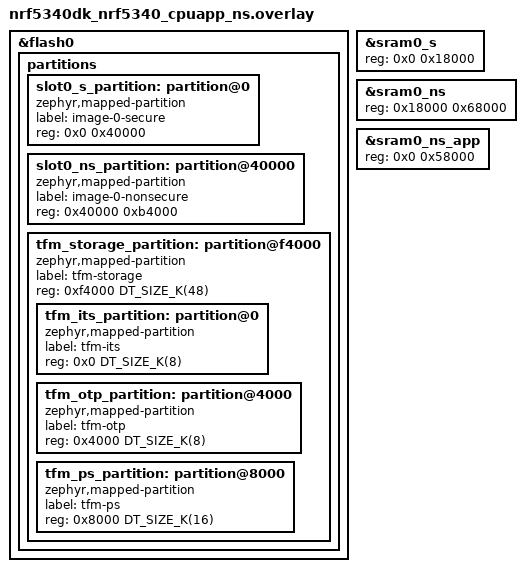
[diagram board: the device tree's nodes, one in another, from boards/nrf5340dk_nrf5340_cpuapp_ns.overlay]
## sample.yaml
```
sample:
  description: Wi-Fi Fundamentals Course by Nordic Developer Academy (https://academy.nordicsemi.com/)
  name: Wi-Fi Fundamentals Course - Lesson 2 Exercise 2 Solution
  
common: 
    sysbuild: true
    build_only: true
    
tests:
  wifi_fund.l2.e2_sol.nrf5340dk: 
    extra_args: SHIELD=nrf7002ek
    integration_platforms: 
      - nrf5340dk/nrf5340/cpuapp/ns
      - nrf5340dk/nrf5340/cpuapp
    platform_allow:
      - nrf5340dk/nrf5340/cpuapp/ns
      - nrf5340dk/nrf5340/cpuapp
  
  wifi_fund.l2.e2_sol.nrf7002dk:
    integration_platforms: 
      - nrf7002dk/nrf5340/cpuapp/ns
      - nrf7002dk/nrf5340/cpuapp    
    platform_allow:
      - nrf7002dk/nrf5340/cpuapp/ns
      - nrf7002dk/nrf5340/cpuapp
  
```

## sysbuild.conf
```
#
# Copyright (c) 2024 Nordic Semiconductor ASA
#
# SPDX-License-Identifier: LicenseRef-Nordic-5-Clause
#

# STEP 1.1 - Enable Wi-Fi in Sysbuild
SB_CONFIG_WIFI_NRF70=y
```

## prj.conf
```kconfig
#
# Copyright (c) 2022 Nordic Semiconductor ASA
#
# SPDX-License-Identifier: LicenseRef-Nordic-5-Clause
#

# Wi-Fi
# STEP 1.2 - Enable the Wi-Fi relevant configurations
CONFIG_WIFI=y
CONFIG_WIFI_NM_WPA_SUPPLICANT=y

# STEP 1.3 - Optimize Wi-Fi stack to save memory
CONFIG_NRF70_RX_NUM_BUFS=16
CONFIG_NRF70_MAX_TX_AGGREGATION=4

# STEP 2 - Configure the Wi-Fi credentials
CONFIG_WIFI_CREDENTIALS=y
# STEP 12.1 - Disable static Wi-Fi network configuration
CONFIG_WIFI_CREDENTIALS_STATIC=n
CONFIG_WIFI_CREDENTIALS_STATIC_SSID="<your_network_SSID>"
CONFIG_WIFI_CREDENTIALS_STATIC_PASSWORD="<your_network_password>"

# STEP 1.4 - Enable the Network Management relevant configurations
CONFIG_NET_MGMT=y
CONFIG_NET_MGMT_EVENT=y
CONFIG_NET_MGMT_EVENT_INFO=y

# STEP 1.5 - Enable the Connection Manager and L2 connectivity
CONFIG_NET_CONNECTION_MANAGER=y
CONFIG_NET_CONNECTION_MANAGER_MONITOR_STACK_SIZE=5200
CONFIG_L2_WIFI_CONNECTIVITY=y
# STEP 14 - Enable the auto connect feature of the L2 Wi-Fi connectivity
CONFIG_L2_WIFI_CONNECTIVITY_AUTO_CONNECT=n

# STEP 13 - Enable support for shell commands
CONFIG_SHELL=y
CONFIG_NET_L2_WIFI_SHELL=y
CONFIG_WIFI_CREDENTIALS_SHELL=y
CONFIG_SHELL_STACK_SIZE=5200

# Logging
CONFIG_LOG=y

# DK library
CONFIG_DK_LIBRARY=y

# System settings
CONFIG_NEWLIB_LIBC=y
CONFIG_NEWLIB_LIBC_NANO=n

# Networking
CONFIG_NETWORKING=y
CONFIG_NET_SOCKETS=y
CONFIG_NET_L2_ETHERNET=y
CONFIG_NET_IPV4=y
CONFIG_NET_IPV6=n
CONFIG_NET_DHCPV4=y

# Memory
CONFIG_SYSTEM_WORKQUEUE_STACK_SIZE=4096
CONFIG_MAIN_STACK_SIZE=5200
```

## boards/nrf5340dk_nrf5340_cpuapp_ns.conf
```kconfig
# STEP 12.2 - Create a board-specific file for building with TF-M
CONFIG_WIFI_CREDENTIALS_BACKEND_PSA=y
CONFIG_TFM_PROFILE_TYPE_MEDIUM=y
```

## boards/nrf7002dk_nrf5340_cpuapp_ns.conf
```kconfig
# UART1 is used for TF-M logging should be disabled
CONFIG_TFM_SECURE_UART=n
CONFIG_TFM_LOG_LEVEL_SILENCE=y

# STEP 12.2 - Create a board-specific file for building with TF-M
CONFIG_WIFI_CREDENTIALS_BACKEND_PSA=y
CONFIG_TFM_PROFILE_TYPE_MEDIUM=y
```

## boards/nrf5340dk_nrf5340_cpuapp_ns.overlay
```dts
/*
 * Copyright (c) 2026 Nordic Semiconductor ASA
 *
 * SPDX-License-Identifier: LicenseRef-Nordic-5-Clause
 */

/delete-node/ &boot_partition;
/delete-node/ &slot0_partition;
/delete-node/ &slot1_partition;
/delete-node/ &tfm_its_partition;
/delete-node/ &tfm_otp_partition;
/delete-node/ &tfm_ps_partition;

&flash0 {
    partitions {
        slot0_s_partition: partition@0 {
            compatible = "zephyr,mapped-partition";
            label = "image-0-secure";
            reg = <0x0 0x40000>;
        };

        slot0_ns_partition: partition@40000 {
            compatible = "zephyr,mapped-partition";
            label = "image-0-nonsecure";
            reg = <0x40000 0xb4000>;
        };

        tfm_storage_partition: partition@f4000 {
            compatible = "zephyr,mapped-partition";
            label = "tfm-storage";
            reg = <0xf4000 DT_SIZE_K(48)>;
            ranges = <0x0 0xf4000 DT_SIZE_K(48)>;
            #address-cells = <1>;
            #size-cells = <1>;

            tfm_its_partition: partition@0 {
                compatible = "zephyr,mapped-partition";
                label = "tfm-its";
                reg = <0x0 DT_SIZE_K(8)>;
            };

            tfm_otp_partition: partition@4000 {
                compatible = "zephyr,mapped-partition";
                label = "tfm-otp";
                reg = <0x4000 DT_SIZE_K(8)>;
            };

            tfm_ps_partition: partition@8000 {
                compatible = "zephyr,mapped-partition";
                label = "tfm-ps";
                reg = <0x8000 DT_SIZE_K(16)>;
            };
        };
    };
};

/*
 * TrustZone SRAM split from devicetree (region_defs.h for TF-M). The secure image uses
 * 96 KiB (0x18000) at the base of cpuapp SRAM (&sram0_s); NS RAM begins at 0x20000000 + 0x18000.
 * &sram0_ns spans 0x68000 bytes; &sram0_ns_app is 0x58000 because the top 0x10000 (64 KiB)
 * within that NS window is sram0_shared for application/network-core IPC
 * (nrf5340_shared_sram_partition.dtsi), i.e. 0x58000 + 0x10000 == 0x68000.
 */
&sram0_s {
    reg = <0x0 0x18000>;
};

&sram0_ns {
    reg = <0x18000 0x68000>;
    ranges = <0x0 0x18000 0x68000>;
};

&sram0_ns_app {
    reg = <0x0 0x58000>;
};
```

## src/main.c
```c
/*
 * Copyright (c) 2023 Nordic Semiconductor ASA
 *
 * SPDX-License-Identifier: LicenseRef-Nordic-5-Clause
 */

#include <errno.h>
#include <stddef.h>
#include <string.h>
#include <stdio.h>
#include <zephyr/kernel.h>
#include <zephyr/types.h>
#include <zephyr/logging/log.h>

#include <dk_buttons_and_leds.h>

/* STEP 3 - Include the necessary header files */
#include <zephyr/net/net_mgmt.h>
#include <zephyr/net/wifi_mgmt.h>
#include <zephyr/net/wifi_credentials.h>

LOG_MODULE_REGISTER(Lesson2_Exercise2, LOG_LEVEL_INF);

/* STEP 4 - Define a macro for the relevant network events */
#define EVENT_MASK (NET_EVENT_L4_CONNECTED | NET_EVENT_L4_DISCONNECTED)

/* STEP 5 - Declare the callback structure for Wi-Fi events */
static struct net_mgmt_event_callback mgmt_cb;

/* STEP 6.1 - Define the boolean connected and the semaphore run_app */
static bool connected;
static K_SEM_DEFINE(run_app, 0, 1);

/* STEP 6.2 - Define the callback function for network events */
static void net_mgmt_event_handler(struct net_mgmt_event_callback *cb,
			  uint64_t mgmt_event, struct net_if *iface)
{
	if ((mgmt_event & EVENT_MASK) != mgmt_event) {
		return;
	}
	if (mgmt_event == NET_EVENT_L4_CONNECTED) {
		LOG_INF("Network connected");
		connected = true;
		dk_set_led_on(DK_LED1);
		k_sem_give(&run_app);
		return;
	}
	if (mgmt_event == NET_EVENT_L4_DISCONNECTED) {
		if (connected == false) {
			LOG_INF("Waiting for network to be connected");
		} else {
			dk_set_led_off(DK_LED1);
			LOG_INF("Network disconnected");
			connected = false;
		}
		k_sem_reset(&run_app);
		return;
	}
}

#ifdef CONFIG_WIFI_CREDENTIALS_STATIC 
/* STEP 8 - Define the function to populate the Wi-Fi credential parameters */
static int wifi_args_to_params(struct wifi_connect_req_params *params)
{

	/* STEP 8.1 - Populate the SSID and password */
	params->ssid = CONFIG_WIFI_CREDENTIALS_STATIC_SSID;
	params->ssid_length = strlen(params->ssid);

	params->psk = CONFIG_WIFI_CREDENTIALS_STATIC_PASSWORD;
	params->psk_length = strlen(params->psk);

	/* STEP 8.2 - Populate the rest of the relevant members */
	params->channel = WIFI_CHANNEL_ANY;
	params->security = WIFI_SECURITY_TYPE_PSK;
	params->mfp = WIFI_MFP_OPTIONAL;
	params->timeout = SYS_FOREVER_MS;
	params->band = WIFI_FREQ_BAND_UNKNOWN;
	memset(params->bssid, 0, sizeof(params->bssid));
	return 0;
}
#endif //CONFIG_WIFI_CREDENTIALS_STATIC

int main(void)
{
	if (dk_leds_init() != 0) {
		LOG_ERR("Failed to initialize the LED library");
	}

	LOG_INF("Initializing Wi-Fi driver");
	/* Sleep to allow initialization of Wi-Fi driver */
	k_sleep(K_SECONDS(1));

	/* STEP 7 - Initialize and add the callback function for network events */
	net_mgmt_init_event_callback(&mgmt_cb, net_mgmt_event_handler, EVENT_MASK);
	net_mgmt_add_event_callback(&mgmt_cb);

	#ifdef CONFIG_WIFI_CREDENTIALS_STATIC 
	/* STEP 9.1 - Declare the variable for the network configuration parameters */
	struct wifi_connect_req_params cnx_params;

	/* STEP 9.2 - Get the network interface */
	struct net_if *iface = net_if_get_first_wifi();
	if (iface == NULL) {
		LOG_ERR("Returned network interface is NULL");
		return -1;
	}

	/* STEP 10 - Populate cnx_params with the network configuration */
	wifi_args_to_params(&cnx_params);

	/* STEP 11 - Call net_mgmt() to request the Wi-Fi connection */
	LOG_INF("Connecting to Wi-Fi");
	int err = net_mgmt(NET_REQUEST_WIFI_CONNECT, iface, &cnx_params, sizeof(struct wifi_connect_req_params));
	if (err) {
		LOG_ERR("Connecting to Wi-Fi failed, err: %d", err);
		return ENOEXEC;
	}
	#endif //CONFIG_WIFI_CREDENTIALS_STATIC

	k_sem_take(&run_app, K_FOREVER);

	return 0;
}
```
